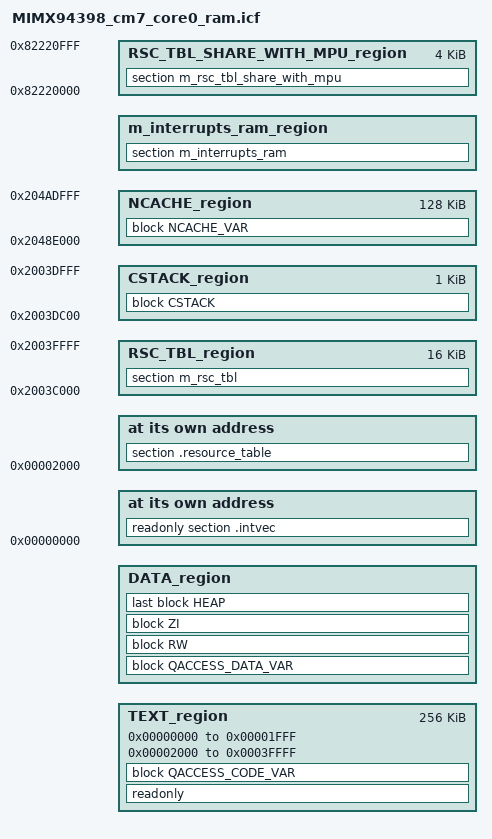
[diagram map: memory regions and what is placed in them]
/*
** ###################################################################
**     Processors:          MIMX94398AVKE_cm7_core0
**                          MIMX94398AVKJ_cm7_core0
**                          MIMX94398AVKM_cm7_core0
**                          MIMX94398AVME_cm7_core0
**                          MIMX94398AVMJ_cm7_core0
**                          MIMX94398AVMM_cm7_core0
**                          MIMX94398CVKE_cm7_core0
**                          MIMX94398CVKJ_cm7_core0
**                          MIMX94398CVKM_cm7_core0
**                          MIMX94398CVME_cm7_core0
**                          MIMX94398CVMJ_cm7_core0
**                          MIMX94398CVMM_cm7_core0
**                          MIMX94398DVKE_cm7_core0
**                          MIMX94398DVKJ_cm7_core0
**                          MIMX94398DVKM_cm7_core0
**                          MIMX94398DVME_cm7_core0
**                          MIMX94398DVMJ_cm7_core0
**                          MIMX94398DVMM_cm7_core0
**                          MIMX94398XVKE_cm7_core0
**                          MIMX94398XVKJ_cm7_core0
**                          MIMX94398XVKM_cm7_core0
**                          MIMX94398XVME_cm7_core0
**                          MIMX94398XVMJ_cm7_core0
**                          MIMX94398XVMM_cm7_core0
**
**     Compiler:            IAR ANSI C/C++ Compiler for ARM
**     Reference manual:    iMX943RM rev1 draftK
**     Version:             rev. 1.0, 2023-11-01
**     Build:               b241111
**
**     Abstract:
**         Linker file for the IAR ANSI C/C++ Compiler for ARM
**
**     Copyright 2016 Freescale Semiconductor, Inc.
**     Copyright 2016-2024 NXP
**     Copyright 2026 NXP
**     SPDX-License-Identifier: BSD-3-Clause
**
**     http:                 www.nxp.com
**     mail:                 support@nxp.com
**
** ###################################################################
*/


define symbol __ram_vector_table_size__ =  isdefinedsymbol(__ram_vector_table__) ? 0x00002000 : 0;
define symbol __ram_vector_table_offset__ =  isdefinedsymbol(__ram_vector_table__) ? 0x00001FFF : 0;

define symbol m_interrupts_start       = 0x00000000;
define symbol m_interrupts_end         = 0x00001FFF;

define symbol m_text_start             = 0x00002000;
define symbol m_text_end               = 0x0003FFFF;

define symbol m_interrupts_ram_start   = 0x20003000;
define symbol m_interrupts_ram_end     = 0x20003000 + __ram_vector_table_offset__;

define symbol m_data_start             = m_interrupts_ram_start + __ram_vector_table_size__;
define symbol m_data_end               = 0x2003DFFF;

define symbol m_ncache_start          = 0x2048E000;
define symbol m_ncache_end            = 0x204ADFFF;

define symbol m_rpmsg_shmem_m71_m70_start          = 0x20039000;
define symbol m_rpmsg_shmem_m71_m70_end            = 0x2003A7FF;

define symbol m_rpmsg_shmem_m33s_m70_start          = 0x2003A800;
define symbol m_rpmsg_shmem_m33s_m70_end            = 0x2003BFFF;

define symbol m_rsc_tbl_start          = 0x2003C000;
define symbol m_rsc_tbl_end            = 0x2003FFFF;

define symbol m_rsc_tbl_share_with_mpu_start  = 0x82220000;
define symbol m_rsc_tbl_share_with_mpu_end    = 0x82220FFF;

/* Sizes */
if (isdefinedsymbol(__stack_size__)) {
  define symbol __size_cstack__        = __stack_size__;
} else {
  define symbol __size_cstack__        = 0x0400;
}

if (isdefinedsymbol(__heap_size__)) {
  define symbol __size_heap__          = __heap_size__;
} else {
  define symbol __size_heap__          = 0x0400;
}

define exported symbol __NCACHE_REGION_START   = m_ncache_start;
define exported symbol __NCACHE_REGION_SIZE    = m_ncache_end - m_ncache_start + 1;

define exported symbol __VECTOR_TABLE  = m_interrupts_start;
define exported symbol __VECTOR_RAM    = isdefinedsymbol(__ram_vector_table__) ? m_interrupts_ram_start : m_interrupts_start;
define exported symbol __RAM_VECTOR_TABLE_SIZE = __ram_vector_table_size__;

define exported symbol __RscTblStart   = m_rsc_tbl_start;
define exported symbol __RscTblEnd     = m_rsc_tbl_end;

define exported symbol __RscTblShareWithMpuStart   = m_rsc_tbl_share_with_mpu_start;
define exported symbol __RscTblShareWithMpuEnd     = m_rsc_tbl_share_with_mpu_end;

define memory mem with size = 4G;
define region TEXT_region = mem:[from m_interrupts_start to m_interrupts_end]
                          | mem:[from m_text_start to m_text_end];
define region DATA_region = mem:[from m_data_start to m_data_end-__size_cstack__];
define region RSC_TBL_region = mem:[from m_rsc_tbl_start to m_rsc_tbl_end];
define region RSC_TBL_SHARE_WITH_MPU_region = mem:[from m_rsc_tbl_share_with_mpu_start to m_rsc_tbl_share_with_mpu_end];
define region CSTACK_region = mem:[from m_data_end-__size_cstack__+1 to m_data_end];
define region NCACHE_region = mem:[from m_ncache_start to m_ncache_end];
define region m_interrupts_ram_region = mem:[from m_interrupts_ram_start to m_interrupts_ram_end];

define block CSTACK    with alignment = 8, size = __size_cstack__   { };
define block HEAP      with alignment = 8, size = __size_heap__     { };
define block RW        { readwrite };
define block ZI        { zi };
define block NCACHE_VAR    { section NonCacheable , section NonCacheable.init };
define block QACCESS_CODE_VAR   with alignment = 32 { section CodeQuickAccess };
define block QACCESS_DATA_VAR   with alignment = 32 { section DataQuickAccess };

initialize by copy { readwrite, section .textrw, section DataQuickAccess };
do not initialize  { section .noinit };

keep{section .resource_table};

place at address mem: m_interrupts_start    { readonly section .intvec };
".resource_table": place at address mem: m_text_start {section .resource_table};
place in TEXT_region                        { readonly };
place in TEXT_region                        { block QACCESS_CODE_VAR };
place in DATA_region                        { block QACCESS_DATA_VAR };
place in DATA_region                        { block RW };
place in DATA_region                        { block ZI };
place in DATA_region                        { last block HEAP };
place in CSTACK_region                      { block CSTACK };
place in RSC_TBL_region                     { section m_rsc_tbl };
place in RSC_TBL_SHARE_WITH_MPU_region      { section m_rsc_tbl_share_with_mpu };
place in m_interrupts_ram_region            { section m_interrupts_ram };
place in NCACHE_region                      { block NCACHE_VAR };
